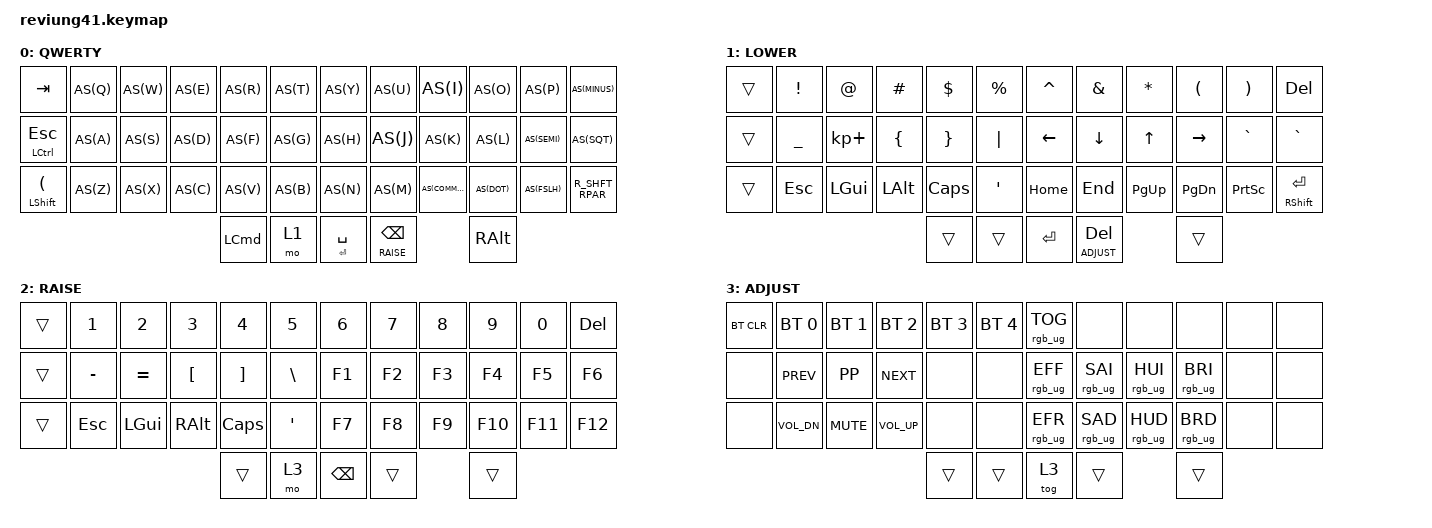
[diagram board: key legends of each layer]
/*
 * Copyright (c) 2020 The ZMK Contributors
 *
 * SPDX-License-Identifier: MIT
 */

#include <behaviors.dtsi>
#include <dt-bindings/zmk/keys.h>
#include <dt-bindings/zmk/bt.h>
#include <dt-bindings/zmk/rgb.h>

#define QWERTY 0
#define LOWER 1
#define RAISE 2
#define ADJUST 3

#define AS(keycode) &as LS(keycode) keycode

#define CTR_ESC &mt LCTRL ESC
#define L_SHFT_PAR &mt LSHFT LPAR
#define R_SHFT_PAR &mt RSHFT RPAR
#define SPC_RET &mt RET SPACE
#define RSE_BSPC &lt RAISE BSPC
#define ADJ_DEL &lt ADJUST DEL

/ {
        behaviors {
            as: auto_shift {
                compatible = "zmk,behavior-hold-tap";
                label = "AUTO_SHIFT";
                #binding-cells = <2>;
                tapping_term_ms = <175>;
                quick_tap_ms = <0>;
                flavor = "tap-preferred";
                bindings = <&kp>, <&kp>;
            };
        };

        keymap {
                compatible = "zmk,keymap";

                default_layer {
                        label = "QWERTY";
// -------------------------------------------------------------------------------------
// |  TAB.     |  Q  |  W  |  E  |  R  |  T  |   |  Y  |  U   |  I  |  O  |  P  |    -      |
// | CTRL/Esc  |  A  |  S  |  D  |  F  |  G  |   |  H  |  J   |  K  |  L  |  ;  |    '      |
// | LShft     |  Z  |  X  |  C  |  V  |  B  |   |  N  |  M   |  ,  |  .  |  /  |   SHFT)   |
//                         | ALT | LWR | SPC | RSE  | ALT |
                        bindings = <
   &kp TAB    AS(Q) AS(W) AS(E) AS(R) AS(T)   AS(Y) AS(U)  AS(I)     AS(O)   AS(P)    AS(MINUS)
   CTR_ESC    AS(A) AS(S) AS(D) AS(F) AS(G)   AS(H) AS(J)  AS(K)     AS(L)   AS(SEMI) AS(SQT)
   L_SHFT_PAR AS(Z) AS(X) AS(C) AS(V) AS(B)   AS(N) AS(M)  AS(COMMA) AS(DOT) AS(FSLH) R_SHFT_RPAR
                               &kp LCMD  &mo 1 SPC_RET RSE_BSPC  &kp RALT
                        >;
                };

                lower_layer {
                        label = "LOWER";
// ----------------------------------------------------------------------------------
// |    |  !  |  @  |  #  |  $  |  %  |   |  ^  |  &  |  *  |  (  |  )  |    DEL    |
// |    |  _  |  +  |  {  |  }  | "|" |   | LFT | DWN |  UP | RGT |  `  |     ~     |
// |    | ESC | GUI | ALT | CAPS|  "  |   | HOME| END | PGUP| PGDN| PRSC| SHFT(RET) |
//                       |     |     | RET | ADJ |     |
                        bindings = <
   &trans &kp EXCL  &kp AT      &kp HASH &kp DLLR &kp PRCNT      &kp CARET &kp AMPS &kp STAR  &kp LPAR  &kp RPAR  &kp DEL
   &trans &kp UNDER &kp KP_PLUS &kp LBRC &kp RBRC &kp PIPE       &kp LEFT  &kp DOWN &kp UP    &kp RIGHT &kp GRAVE &kp GRAVE
   &trans &kp ESC   &kp LGUI    &kp LALT &kp CLCK &kp SQT        &kp HOME  &kp END  &kp PG_UP &kp PG_DN &kp PSCRN &mt RSHFT RET
                                 &trans      &trans       &kp RET        ADJ_DEL       &trans
                        >;
                };

                raise_layer {
                        label = "RAISE";
// -----------------------------------------------------------------------------------------
// |    |  1  |  2  |  3  |  4  |  5  |   |  6  |  7  |  8  |  9  |  0  | DEL |
// |    |  -  |  =  |  [  |  ]  |  \  |   | F1  | F2  | F3  | F4  | F5  | F6  |
// |    | ESC | GUI | ALT | CAPS|  "  |   | F7  | F8  | F9  | F10 | F11 | F12 |
//                       |     | ADJ | BKSP |    |     |
                        bindings = <
   &trans &kp N1    &kp N2    &kp N3    &kp N4    &kp N5        &kp N6    &kp N7    &kp N8    &kp N9    &kp N0    &kp DEL
   &trans &kp MINUS &kp EQUAL &kp LBKT  &kp RBKT  &kp BSLH      &kp F1    &kp F2    &kp F3    &kp F4    &kp F5    &kp F6
   &trans &kp ESC   &kp LGUI  &kp RALT  &kp CLCK  &kp SQT       &kp F7    &kp F8    &kp F9    &kp F10   &kp F11   &kp F12
                                &trans      &mo 3       &kp BSPC        &trans      &trans
                        >;
                };

                adjust_layer {
                        label = "ADJUST";
// -----------------------------------------------------------------------------------------
// | BTCLR| BT0      | BT1    | BT2      | BT3   | BT4 |       | RGB TOG  |          |          |          |  |  |
// |      | K_PREV   | K_PP   | K_NEXT   |       |     |       | RGB ANI+ | RGB SAT+ | RGB HUE+ | RGB BRI+ |  |  |
// |      | K_VOL_DN | K_MUTE | K_VOL_UP |       |     |       | RGB ANI- | RGB SAT- | RGB HUE- | RGB BRI+ |  |  |
//                                       |       |     |       |          |          |

                        bindings = <
    &bt BT_CLR &bt BT_SEL 0 &bt BT_SEL 1 &bt BT_SEL 2 &bt BT_SEL 3 &bt BT_SEL 4      &rgb_ug RGB_TOG            &none            &none            &none            &none  &none
    &none  &kp K_PREV    &kp K_PP    &kp K_NEXT    &none  &none      &rgb_ug RGB_EFF  &rgb_ug RGB_SAI  &rgb_ug RGB_HUI  &rgb_ug RGB_BRI  &none  &none
    &none  &kp K_VOL_DN  &kp K_MUTE  &kp K_VOL_UP  &none  &none      &rgb_ug RGB_EFR  &rgb_ug RGB_SAD  &rgb_ug RGB_HUD  &rgb_ug RGB_BRD  &none  &none
                                      &trans      &trans       &tog 3        &trans      &trans
                        >;
                };
        };
};
